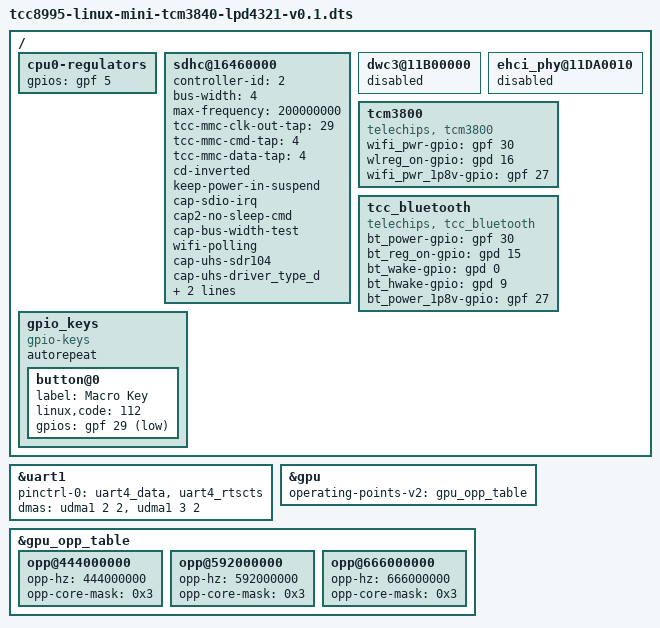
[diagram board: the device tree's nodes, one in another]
/*
 * Device tree for Telechips TCC8990 STB board
 *
 * Copyright (C) 2018 Telechips Inc. - http://www.telechips.com
 *
 * This file is dual-licensed: you can use it either under the terms
 * of the GPL or the X11 license, at your option. Note that this dual
 * licensing only applies to this file, and not this project as a
 * whole.
 *
 *  a) This file is free software; you can redistribute it and/or
 *     modify it under the terms of the GNU General Public License as
 *     published by the Free Software Foundation; either version 2 of the
 *     License, or (at your option) any later version.
 *
 *     This file is distributed in the hope that it will be useful,
 *     but WITHOUT ANY WARRANTY; without even the implied warranty of
 *     MERCHANTABILITY or FITNESS FOR A PARTICULAR PURPOSE.  See the
 *     GNU General Public License for more details.
 *
 * Or, alternatively,
 *
 *  b) Permission is hereby granted, free of charge, to any person
 *     obtaining a copy of this software and associated documentation
 *     files (the "Software"), to deal in the Software without
 *     restriction, including without limitation the rights to use,
 *     copy, modify, merge, publish, distribute, sublicense, and/or
 *     sell copies of the Software, and to permit persons to whom the
 *     Software is furnished to do so, subject to the following
 *     conditions:
 *
 *     The above copyright notice and this permission notice shall be
 *     included in all copies or substantial portions of the Software.
 *
 *     THE SOFTWARE IS PROVIDED "AS IS", WITHOUT WARRANTY OF ANY KIND,
 *     EXPRESS OR IMPLIED, INCLUDING BUT NOT LIMITED TO THE WARRANTIES
 *     OF MERCHANTABILITY, FITNESS FOR A PARTICULAR PURPOSE AND
 *     NONINFRINGEMENT. IN NO EVENT SHALL THE AUTHORS OR COPYRIGHT
 *     HOLDERS BE LIABLE FOR ANY CLAIM, DAMAGES OR OTHER LIABILITY,
 *     WHETHER IN AN ACTION OF CONTRACT, TORT OR OTHERWISE, ARISING
 *     FROM, OUT OF OR IN CONNECTION WITH THE SOFTWARE OR THE USE OR
 *     OTHER DEALINGS IN THE SOFTWARE.
 */

/dts-v1/;

#include "tcc8995-linux-mini.dtsi"

/ {
	/* Describe here after remove this statement if you have something to be override. */
	/* CPU Power Control */
	cpu0-regulators {
		gpios = <&gpf 5 0x4>;
	};

	/* SDIO */
	sdhc@16460000 {
		status = "okay";
		controller-id = <2>;
		bus-width = <4>;
		max-frequency = <200000000>;
		pinctrl-names = "default", "active";

		tcc-mmc-clk-out-tap = <29>;
		tcc-mmc-cmd-tap = <4>;
		tcc-mmc-data-tap = <4>;

		cd-inverted;
		//wp-inverted;
		//non-removable;
		//broken-cd;
		keep-power-in-suspend;
		//enable-sdio-wakeup;
		//cap-power-off-card;
		cap-sdio-irq;
		cap2-no-sleep-cmd;
		cap-bus-width-test;

		//wp-gpios = <&gpb 7 0>;
		//cd-gpios = <&gpext1 5 0>;
		//vctrl-gpio = <&gpsd 10 0>;
		//pwr-gpio = <&gpext2 7 0>;

		//cd-polling;
		wifi-polling;

		/* High-speed SDR */
		//cap-sd-highspeed;
		//cap-mmc-highspeed;

		/* High-speed DDR(emmc & SD3.0 DDR50) */
		//cap-1-8V-ddr;
		//cap-uhs-ddr50;

		/* SD3.0 Common */
		//cap-vdd-165-195;

		/* SD3.0 SDR12 */
		//cap-uhs-sdr12;

		/* SD3.0 SDR25 */
		//cap-uhs-sdr25;
		//cap-uhs-driver_type_a;

		/* SD3.0 SDR50 */
		//cap-uhs-sdr50;
		//cap-uhs-driver_type_c;

		/* SD3.0 SDR104 */
		cap-uhs-sdr104;
		cap-uhs-driver_type_d;
		cap-uhs-cmd23;
		cap-adma;

		/* eMMC HS200 */
		//mmc-hs200-1_8v;
		//cap-uhs-driver_type_d;
		//cap-uhs-cmd23;
		//cap-adma;
	};

	/* USB 3.0 DRD */
	dwc3@11B00000 {
		status = "disable";
		//usb3en-ctrl-able;
		//usb3en-gpio = <&gpc 22 0>;
		//vbus-source-ctrl;
		//vbus-ctrl-able;
		//vbus-gpio = <&gpd 19 0>;
		//pinctrl-names = "default";
		//vdd_dwc-supply = <&vdd_v5p0_reg>;
	};

	/* USB 2.0 HOST */
	ehci_phy@11DA0010{
		status = "disable";
		//vbus-ctrl-able;
		//vbus-gpio = <&gpd 15 0>;
	};

	tcm3800 {
		compatible = "telechips, tcm3800";
		wifi_pwr-gpio = <&gpf 30 0>;
		wlreg_on-gpio = <&gpd 16 0>;
		wifi_pwr_1p8v-gpio = <&gpf 27 0>;
		//wifi_pwr_3p3v-gpio = <&gpsd1 7 0>;
	};

	tcc_bluetooth {
		compatible = "telechips, tcc_bluetooth";
		bt_power-gpio = <&gpf 30 0>; /* BTWIFI_VBAT_EN */
		bt_reg_on-gpio = <&gpd 15 0>;
		bt_wake-gpio = <&gpd 0 0>;
		bt_hwake-gpio = <&gpd 9 0>;
		bt_power_1p8v-gpio = <&gpf 27 0>;
		//bt_power_3p3v-gpio = <&gpsd1 7 0>;
		status = "okay";
	};

	gpio_keys {
		compatible = "gpio-keys";
		#address-cells = <1>;
		#size-cells = <0>;
		autorepeat;
		button@0 {
			label = "Macro Key";
			linux,code = <112>;
			gpios = <&gpf 29 1>;
		};
	};
};

/* bluetooth */
&uart1 {
	pinctrl-names = "default";
	pinctrl-0 = <&uart4_data &uart4_rtscts>;
	dmas = <&udma1 2 2 &udma1 3 2>;
	dma-names = "tx", "rx";
	status = "okay";
};

&gpu {
        operating-points-v2 = <&gpu_opp_table>;
};

&gpu_opp_table {
    opp@444000000 {
	opp-hz = /bits/ 64 <444000000>;
	opp-core-mask = /bits/ 64 <0x3>;
    };
    opp@592000000 {
        opp-hz = /bits/ 64 <592000000>;
        opp-core-mask = /bits/ 64 <0x3>;
    };
    opp@666000000 {
        opp-hz = /bits/ 64 <666000000>;
        opp-core-mask = /bits/ 64 <0x3>;
    };
};
